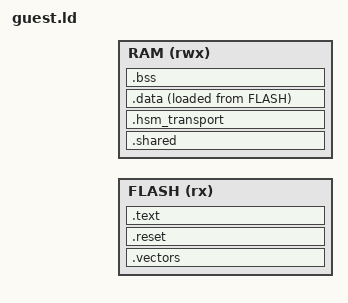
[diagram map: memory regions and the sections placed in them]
/* Link script for stm32h563-tpm NS guests.
 *
 * Copyright (C) 2026 wolfSSL Inc.
 *
 * This file is part of wolfTrust.
 *
 * wolfTrust is free software; you can redistribute it and/or modify
 * it under the terms of the GNU General Public License as published by
 * the Free Software Foundation; either version 3 of the License, or
 * (at your option) any later version.
 *
 * wolfTrust is distributed in the hope that it will be useful,
 * but WITHOUT ANY WARRANTY; without even the implied warranty of
 * MERCHANTABILITY or FITNESS FOR A PARTICULAR PURPOSE.  See the
 * GNU General Public License for more details.
 *
 * You should have received a copy of the GNU General Public License
 * along with this program; if not, write to the Free Software
 * Foundation, Inc., 51 Franklin Street, Fifth Floor, Boston, MA 02110-1335, USA
 */

ENTRY(Reset_Handler)

MEMORY {
  FLASH (rx) : ORIGIN = GUEST_FLASH_ORIGIN, LENGTH = GUEST_FLASH_LENGTH
  RAM   (rwx): ORIGIN = GUEST_RAM_ORIGIN, LENGTH = GUEST_RAM_LENGTH
}

_estack = ORIGIN(RAM) + LENGTH(RAM);
_sidata = LOADADDR(.data);

SECTIONS {
  /* Shared status area at the bottom of NS RAM, reserved by the monitor
   * convention; nothing in this test uses it but the secure side reserves
   * 0..0x100 across guests. */
  .shared ORIGIN(RAM) (NOLOAD) : {
    *(.shared*)
  } > RAM

  /* wolfHSM CMSE transport buffer is kept as a NOLOAD reservation so we
   * never collide with it if the secure side decides to write a status
   * byte; this test does not use HSM. */
  .hsm_transport (ORIGIN(RAM) + 0x100) (NOLOAD) : {
    _hsm_transport_base = .;
    . += 0x200;
    _hsm_transport_end = .;
  } > RAM

  .vectors GUEST_FLASH_ORIGIN : {
    KEEP(*(.vectors))
  } > FLASH

  .reset : {
    KEEP(*(.reset))
  } > FLASH

  .text : {
    *(.text*)
    *(.rodata*)
    *(.ARM.extab* .gnu.linkonce.armextab.*)
    *(.ARM.exidx* .gnu.linkonce.armexidx.*)
  } > FLASH

  .data : {
    _sdata = .;
    *(.data*)
    _edata = .;
  } > RAM AT > FLASH

  .bss (NOLOAD) : {
    _sbss = .;
    *(.bss*)
    *(COMMON)
    _ebss = .;
  } > RAM
}
